# STM32H757xx_CM4 register map
File version: 1.0
Registers are 32-bit, read-write, reset 0x0 unless marked. A register's access mark holds for its fields unless they carry their own. Offsets are from the block's base; [hi:lo] are bit positions; {n}, {i} and the like mark numbered series; 'fields as' and 'values as' point back to an identical list.

## DMAMUX1
Base 0x40020800
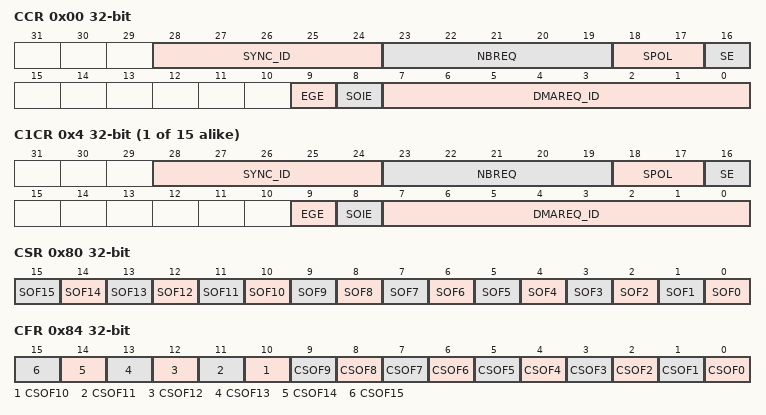
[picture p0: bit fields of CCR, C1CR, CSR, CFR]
0x00 CCR — DMA Multiplexer Channel x Control Register
  [28:24] SYNC_ID — Synchronization identification
  [23:19] NBREQ — Number of DMA requests minus 1 to forward
  [18:17] SPOL — Synchronization polarity
  [16] SE — Synchronization enable
  [9] EGE — Event generation enable
  [8] SOIE — Synchronization overrun interrupt enable
  [7:0] DMAREQ_ID — DMA request identification
{0x0+4i} C{i}CR (i=1..15) — DMA Multiplexer Channel x Control Register
  fields as CCR
0x80 CSR — DMA Channel Status Register
  [n] SOF{n} (n=0..15) — Channel {n} Synchronization overrun event flag
0x84 CFR — DMA Channel Clear Flag Register
  [n] CSOF{n} (n=0..15) — Channel {n} Clear synchronization overrun event flag
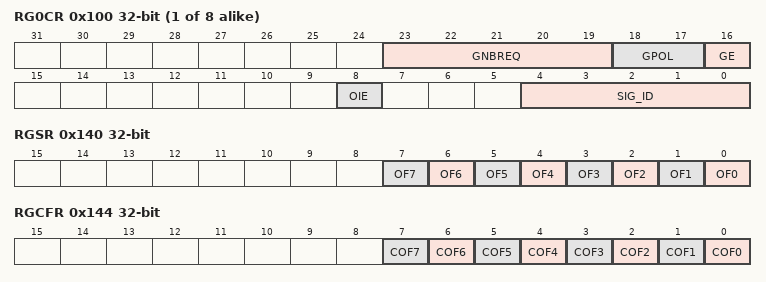
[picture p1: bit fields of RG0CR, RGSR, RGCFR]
{0x100+4i} RG{i}CR (i=0..7) — DMA Request Generator x Control Register
  [23:19] GNBREQ — Number of DMA requests to be generated
  [18:17] GPOL — DMA request generator trigger polarity
  [16] GE — DMA request generator enable
  [8] OIE — Trigger overrun interrupt enable
  [4:0] SIG_ID — Signal identification
0x140 RGSR — DMA Request Generator Status Register
  [n] OF{n} (n=0..7) — Request generator channel {n} Trigger overrun event flag
0x144 RGCFR — DMA Request Generator Clear Flag Register
  [n] COF{n} (n=0..7) — Request generator channel {n} Clear trigger overrun event flag

## DMAMUX2
Base 0x58025800
Registers as DMAMUX1, without C{n}CR (n=8..15).

## ART
Base 0x40024400
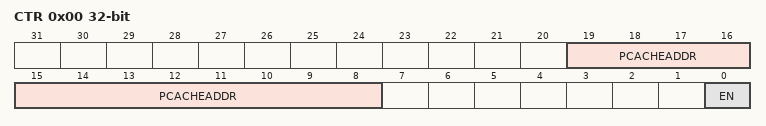
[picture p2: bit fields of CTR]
0x00 CTR — ART accelerator - control register
  [19:8] PCACHEADDR — Cacheable page index
  [0] EN — Cache enable

## DCMI
Base 0x48020000
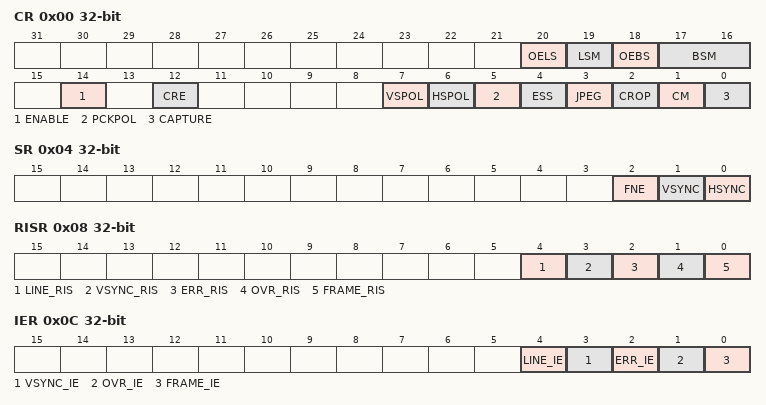
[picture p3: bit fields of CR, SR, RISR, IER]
0x00 CR — DCMI control register 1
  [20] OELS, [19] LSM, [18] OEBS, [17:16] BSM, [14] ENABLE, [12] CRE, [7] VSPOL, [6] HSPOL, [5] PCKPOL, [4] ESS, [3] JPEG, [2] CROP, [1] CM, [0] CAPTURE
0x04 SR — DCMI status register
  [2] FNE, [1] VSYNC, [0] HSYNC
0x08 RISR — DCMI raw interrupt status register
  [4] LINE_RIS, [3] VSYNC_RIS, [2] ERR_RIS, [1] OVR_RIS, [0] FRAME_RIS
0x0C IER — DCMI interrupt enable register
  [4] LINE_IE, [3] VSYNC_IE, [2] ERR_IE, [1] OVR_IE, [0] FRAME_IE
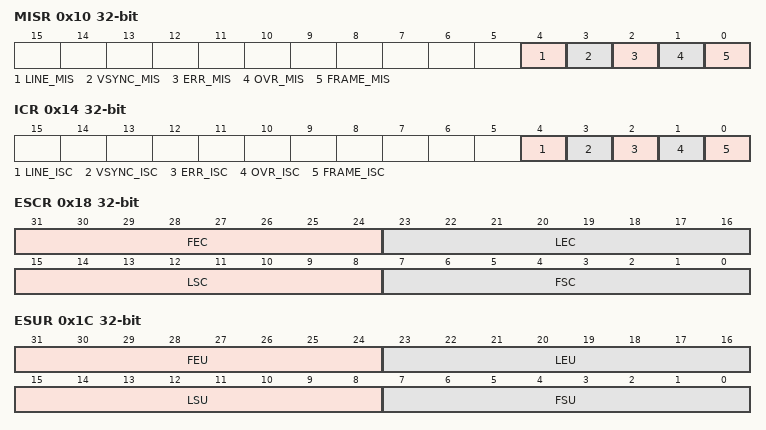
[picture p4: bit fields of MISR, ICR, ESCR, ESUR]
0x10 MISR — DCMI masked interrupt status register
  [4] LINE_MIS, [3] VSYNC_MIS, [2] ERR_MIS, [1] OVR_MIS, [0] FRAME_MIS
0x14 ICR — DCMI interrupt clear register
  [4] LINE_ISC, [3] VSYNC_ISC, [2] ERR_ISC, [1] OVR_ISC, [0] FRAME_ISC
0x18 ESCR — DCMI embedded synchronization code register
  [31:24] FEC, [23:16] LEC, [15:8] LSC, [7:0] FSC
0x1C ESUR — DCMI embedded synchronization unmask register
  [31:24] FEU, [23:16] LEU, [15:8] LSU, [7:0] FSU
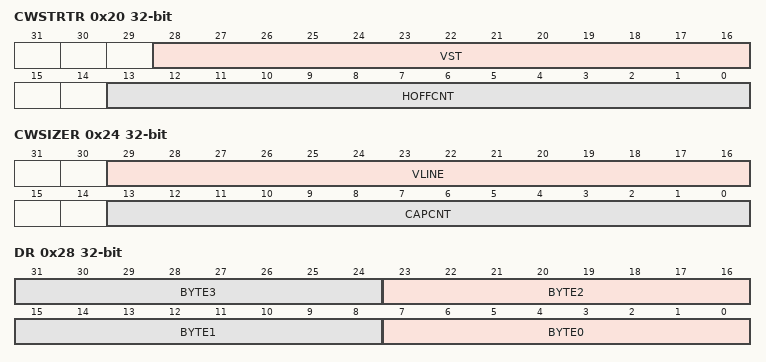
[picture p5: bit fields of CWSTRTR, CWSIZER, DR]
0x20 CWSTRTR — DCMI crop window start
  [28:16] VST, [13:0] HOFFCNT
0x24 CWSIZER — DCMI crop window size
  [29:16] VLINE, [13:0] CAPCNT
0x28 DR — DCMI data register
  [8n+7:8n] BYTE{n} (n=0..3)

## CRYP — Crypto Processor
Base 0x48021000
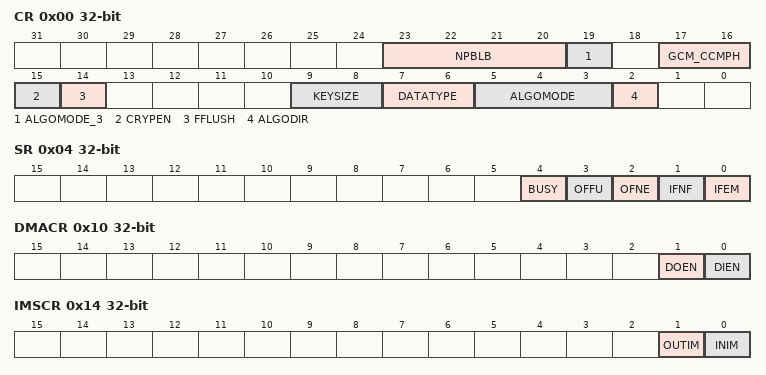
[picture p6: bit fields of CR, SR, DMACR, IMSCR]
0x00 CR — CRYP control register
  [23:20] NPBLB, [19] ALGOMODE_3, [17:16] GCM_CCMPH, [15] CRYPEN, [14] FFLUSH, [9:8] KEYSIZE, [7:6] DATATYPE, [5:3] ALGOMODE, [2] ALGODIR
0x04 SR — CRYP status register
  [4] BUSY, [3] OFFU, [2] OFNE, [1] IFNF, [0] IFEM
0x08 DIN — CRYP data input register
0x0C DOUT — CRYP data output register
0x10 DMACR — CRYP DMA control register
  [1] DOEN, [0] DIEN
0x14 IMSCR — CRYP interrupt mask set/clear register
  [1] OUTIM, [0] INIM
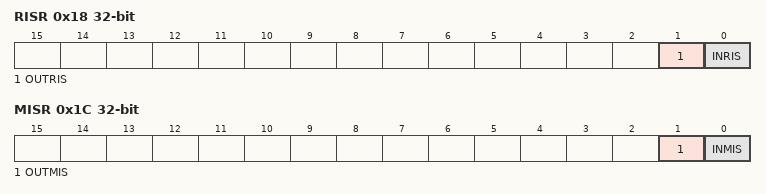
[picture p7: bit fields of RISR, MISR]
0x18 RISR — CRYP raw interrupt status register
  [1] OUTRIS, [0] INRIS
0x1C MISR — CRYP masked interrupt status register
  [1] OUTMIS, [0] INMIS
{0x20+8i} K{i}LR (i=0..3) — CRYP key left register {i}
{0x24+8i} K{i}RR (i=0..3) — CRYP key right register {i}
0x40 IV0LR — CRYP initialization vector left-word register 0
0x44 IV0RR — CRYP initialization vector right-word register 0
0x48 IV1LR — CRYP initialization vector left-word register 1
0x4C IV1RR — CRYP initialization vector right-word register 1
{0x50+4i} CSGCMCCM{i}R (i=0..7) — CRYP GCM/GMAC or CCM/CMAC context swap register {i}
{0x70+4i} CSGCM{i}R (i=0..7) — CRYP GCM/GMAC context swap register {i}
